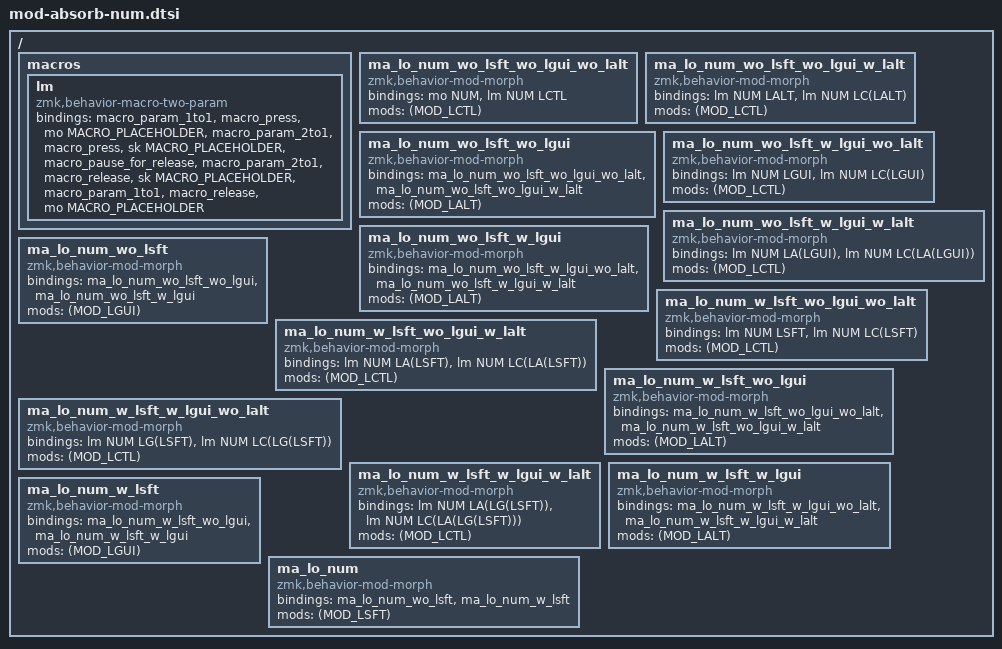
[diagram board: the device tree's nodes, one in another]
/ {
    macros {
        lm: lm {
            compatible = "zmk,behavior-macro-two-param";
            #binding-cells = <2>;
            bindings = <&macro_param_1to1>, <&macro_press &mo MACRO_PLACEHOLDER>,
                <&macro_param_2to1>, <&macro_press &sk MACRO_PLACEHOLDER>,
                <&macro_pause_for_release>,
                <&macro_param_2to1>, <&macro_release &sk MACRO_PLACEHOLDER>,
                <&macro_param_1to1>, <&macro_release &mo MACRO_PLACEHOLDER>;
        };
    };
     ma_lo_num_wo_lsft_wo_lgui_wo_lalt: ma_lo_num_wo_lsft_wo_lgui_wo_lalt {
        compatible = "zmk,behavior-mod-morph";
        #binding-cells = <0>;
        bindings = <&mo NUM>, <&lm NUM LCTL>;

        mods = <(MOD_LCTL)>;
    };

     ma_lo_num_wo_lsft_wo_lgui_w_lalt: ma_lo_num_wo_lsft_wo_lgui_w_lalt {
        compatible = "zmk,behavior-mod-morph";
        #binding-cells = <0>;
        bindings = <&lm NUM LALT>, <&lm NUM LC(LALT)>;

        mods = <(MOD_LCTL)>;
    };

     ma_lo_num_wo_lsft_wo_lgui: ma_lo_num_wo_lsft_wo_lgui {
        compatible = "zmk,behavior-mod-morph";
        #binding-cells = <0>;
        bindings = <&ma_lo_num_wo_lsft_wo_lgui_wo_lalt>, <&ma_lo_num_wo_lsft_wo_lgui_w_lalt>;

        mods = <(MOD_LALT)>;
    };

     ma_lo_num_wo_lsft_w_lgui_wo_lalt: ma_lo_num_wo_lsft_w_lgui_wo_lalt {
        compatible = "zmk,behavior-mod-morph";
        #binding-cells = <0>;
        bindings = <&lm NUM LGUI>, <&lm NUM LC(LGUI)>;

        mods = <(MOD_LCTL)>;
    };

     ma_lo_num_wo_lsft_w_lgui_w_lalt: ma_lo_num_wo_lsft_w_lgui_w_lalt {
        compatible = "zmk,behavior-mod-morph";
        #binding-cells = <0>;
        bindings = <&lm NUM LA(LGUI)>, <&lm NUM LC(LA(LGUI))>;

        mods = <(MOD_LCTL)>;
    };

     ma_lo_num_wo_lsft_w_lgui: ma_lo_num_wo_lsft_w_lgui {
        compatible = "zmk,behavior-mod-morph";
        #binding-cells = <0>;
        bindings = <&ma_lo_num_wo_lsft_w_lgui_wo_lalt>, <&ma_lo_num_wo_lsft_w_lgui_w_lalt>;

        mods = <(MOD_LALT)>;
    };

     ma_lo_num_wo_lsft: ma_lo_num_wo_lsft {
        compatible = "zmk,behavior-mod-morph";
        #binding-cells = <0>;
        bindings = <&ma_lo_num_wo_lsft_wo_lgui>, <&ma_lo_num_wo_lsft_w_lgui>;

        mods = <(MOD_LGUI)>;
    };

     ma_lo_num_w_lsft_wo_lgui_wo_lalt: ma_lo_num_w_lsft_wo_lgui_wo_lalt {
        compatible = "zmk,behavior-mod-morph";
        #binding-cells = <0>;
        bindings = <&lm NUM LSFT>, <&lm NUM LC(LSFT)>;

        mods = <(MOD_LCTL)>;
    };

     ma_lo_num_w_lsft_wo_lgui_w_lalt: ma_lo_num_w_lsft_wo_lgui_w_lalt {
        compatible = "zmk,behavior-mod-morph";
        #binding-cells = <0>;
        bindings = <&lm NUM LA(LSFT)>, <&lm NUM LC(LA(LSFT))>;

        mods = <(MOD_LCTL)>;
    };

     ma_lo_num_w_lsft_wo_lgui: ma_lo_num_w_lsft_wo_lgui {
        compatible = "zmk,behavior-mod-morph";
        #binding-cells = <0>;
        bindings = <&ma_lo_num_w_lsft_wo_lgui_wo_lalt>, <&ma_lo_num_w_lsft_wo_lgui_w_lalt>;

        mods = <(MOD_LALT)>;
    };

     ma_lo_num_w_lsft_w_lgui_wo_lalt: ma_lo_num_w_lsft_w_lgui_wo_lalt {
        compatible = "zmk,behavior-mod-morph";
        #binding-cells = <0>;
        bindings = <&lm NUM LG(LSFT)>, <&lm NUM LC(LG(LSFT))>;

        mods = <(MOD_LCTL)>;
    };

     ma_lo_num_w_lsft_w_lgui_w_lalt: ma_lo_num_w_lsft_w_lgui_w_lalt {
        compatible = "zmk,behavior-mod-morph";
        #binding-cells = <0>;
        bindings = <&lm NUM LA(LG(LSFT))>, <&lm NUM LC(LA(LG(LSFT)))>;

        mods = <(MOD_LCTL)>;
    };

     ma_lo_num_w_lsft_w_lgui: ma_lo_num_w_lsft_w_lgui {
        compatible = "zmk,behavior-mod-morph";
        #binding-cells = <0>;
        bindings = <&ma_lo_num_w_lsft_w_lgui_wo_lalt>, <&ma_lo_num_w_lsft_w_lgui_w_lalt>;

        mods = <(MOD_LALT)>;
    };

     ma_lo_num_w_lsft: ma_lo_num_w_lsft {
        compatible = "zmk,behavior-mod-morph";
        #binding-cells = <0>;
        bindings = <&ma_lo_num_w_lsft_wo_lgui>, <&ma_lo_num_w_lsft_w_lgui>;

        mods = <(MOD_LGUI)>;
    };

     ma_lo_num: ma_lo_num {
        compatible = "zmk,behavior-mod-morph";
        #binding-cells = <0>;
        bindings = <&ma_lo_num_wo_lsft>, <&ma_lo_num_w_lsft>;

        mods = <(MOD_LSFT)>;
    };
};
